# DSS_EDP0_V2A_CORE_VP_REGS_APB register map
Vendor: Texas Instruments
Peripheral module from a debugger description file (folder J7ES).
Registers are 32-bit, access per field, reset 0x0 unless marked. A register's access mark holds for its fields unless they carry their own. Offsets are as the file gives them; lines under a group give offsets from that group; [hi:lo] are bit positions; {n}, {i} and the like mark numbered series; 'fields as' and 'values as' point back to an identical list; <NAME> marks a mode.

## DSS_EDP0_V2A_CORE_VP_REGS_APB (part 1 of 3)
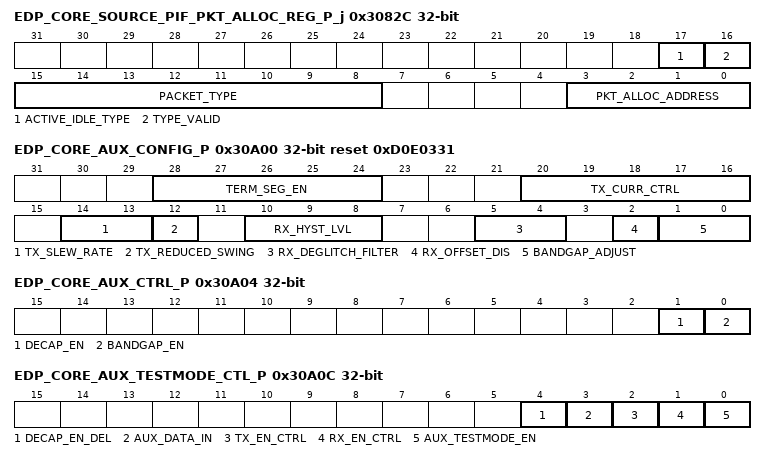
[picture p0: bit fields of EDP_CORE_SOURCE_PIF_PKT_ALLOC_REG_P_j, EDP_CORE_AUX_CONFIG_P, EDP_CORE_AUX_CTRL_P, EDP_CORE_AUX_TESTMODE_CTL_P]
0x3082C EDP_CORE_SOURCE_PIF_PKT_ALLOC_REG_P_j — Packet configuration to be stored in the allocation table Offset = 0003082Ch + (j * 40h); where j = 0h to 3h
  [17] ACTIVE_IDLE_TYPE rw — Indicates in which mode the SDP will be sent.
  [16] TYPE_VALID rw — 1 for valid, 0 for nonvalid
  [15:8] PACKET_TYPE rw
  [3:0] PKT_ALLOC_ADDRESS rw — Address of the register in the source allocation table
0x30830 EDP_CORE_SOURCE_PIF_PKT_ALLOC_WR_EN_P_j — Enable bit for writing to the allocation table Offset = 00030830h + (j * 40h); where j = 0h to 3h
  [0] PKT_ALLOC_WR_EN rw — Enable bit for writing to the allocation table, active high
0x30834 EDP_CORE_SOURCE_PIF_SW_RESET_P_j — Software reset. Offset = 00030834h + (j * 40h); where j = 0h to 3h
  [0] SW_RST rw — Software reset, active high.
0x30838 EDP_CORE_SOURCE_PIF_PPS_HEADER_P_j rw — PPS header Offset = 00030838h + (j * 40h); where j = 0h to 3h
  [31:0] PPS_HEADER — value of the PPS header as per DPv1.4
0x3083C EDP_CORE_SOURCE_PIF_PPS_P_j — PPS SDP indication Offset = 0003083Ch + (j * 40h); where j = 0h to 3h
  [0] PPS rw — PPS SDP indication, active high.
0x30A00 EDP_CORE_AUX_CONFIG_P reset 0xD0E0331 — AUX Configuration Register
  [28:24] TERM_SEG_EN rw — Enables output resistor segments for termination impedance.
  [20:16] TX_CURR_CTRL rw — TX current for output diff pair.
  [14:13] TX_SLEW_RATE rw — TX slew rate adjust.
  [12] TX_REDUCED_SWING rw — Control for lowering AUX transmitter swing level.
  [10:8] RX_HYST_LVL rw — Hysteresis control for AUX receiver front end.
  [5:4] RX_DEGLITCH_FILTER rw — Suppresses high-frequency pulses on AUX receiver output.
  [2] RX_OFFSET_DIS rw — Disables internal receiver cmn mode offset.
  [1:0] BANDGAP_ADJUST rw — Bandgap startup circuit adjust.
0x30A04 EDP_CORE_AUX_CTRL_P — AUX Control Register
  [1] DECAP_EN rw — Decap enable.
  [0] BANDGAP_EN rw — Bandgap enable.
0x30A08 EDP_CORE_AUX_ATBSEL_P — AUX_ATBSEL
  [7:0] AUXIP_ATBSEL_ONEHOT rw
0x30A0C EDP_CORE_AUX_TESTMODE_CTL_P — AUX IP test control register.
  [4] DECAP_EN_DEL rw — decap_en_del test value.
  [3] AUX_DATA_IN rw — aux_data_in test value.
  [2] TX_EN_CTRL rw — tx_en test value.
  [1] RX_EN_CTRL rw — rx_en test value.
  [0] AUX_TESTMODE_EN rw — AUX test enable.
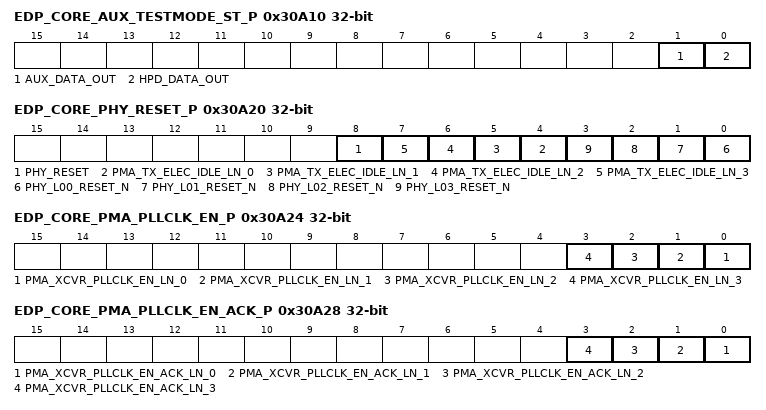
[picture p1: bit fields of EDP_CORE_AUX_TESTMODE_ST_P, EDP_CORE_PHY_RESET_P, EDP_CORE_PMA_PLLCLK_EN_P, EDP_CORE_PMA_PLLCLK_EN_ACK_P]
0x30A10 EDP_CORE_AUX_TESTMODE_ST_P ro — AUX IP interface status.
  [1] AUX_DATA_OUT — Raw status of aux_data_out output from AUX IP
  [0] HPD_DATA_OUT — Raw status of HPD output from AUX IP
0x30A20 EDP_CORE_PHY_RESET_P — PHY Reset Control Register
  [8] PHY_RESET rw
  [n+4] PMA_TX_ELEC_IDLE_LN_{n} rw (n=0..3) — PMA Tx electrical idle for line {n}.
  [n] PHY_L{n:02}_RESET_N rw (n=0..3)
0x30A24 EDP_CORE_PMA_PLLCLK_EN_P — PHY Link PLL Clock Enable Register
  [n] PMA_XCVR_PLLCLK_EN_LN_{n} rw (n=0..3) — Link PLL clock enable used to cleanly turn off the data rate clock in the PMA for line {n},
0x30A28 EDP_CORE_PMA_PLLCLK_EN_ACK_P ro — PHY Link PLL Clock Status Register
  [n] PMA_XCVR_PLLCLK_EN_ACK_LN_{n} (n=0..3) — Link PLL clock enable acknowledgement, indicates whether the data rate clock in the PMA for line {n} is running.
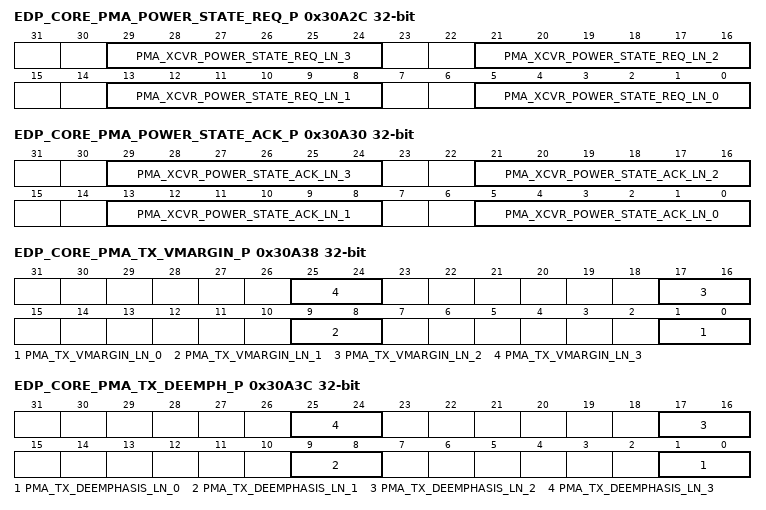
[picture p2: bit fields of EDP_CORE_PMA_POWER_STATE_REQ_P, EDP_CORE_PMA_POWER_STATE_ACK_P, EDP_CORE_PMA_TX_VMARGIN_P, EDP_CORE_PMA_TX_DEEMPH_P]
0x30A2C EDP_CORE_PMA_POWER_STATE_REQ_P — PHY Link Power State Request Register. Please refer to PHY Specification for detailed power state values
  [8n+5:8n] PMA_XCVR_POWER_STATE_REQ_LN_{n} rw (n=0..3) — Change the link power state.
0x30A30 EDP_CORE_PMA_POWER_STATE_ACK_P ro — PHY Link Power State Status Register
  [8n+5:8n] PMA_XCVR_POWER_STATE_ACK_LN_{n} (n=0..3) — Link power state acknowledgement, this signal provides indication that a power state change request has completed.
0x30A34 EDP_CORE_PMA_CMN_READY_P ro — PMA Operation Status Register
  [0] PMA_CMN_READY — PMA common ready,
0x30A38 EDP_CORE_PMA_TX_VMARGIN_P — PMA Tx Voltage Margin Control Register. Please refer to PHY Specification for Voltage Margin settings.
  [8n+1:8n] PMA_TX_VMARGIN_LN_{n} rw (n=0..3) — Drives PMA input tx_vmargin_ln_{n} for the associated lane.
0x30A3C EDP_CORE_PMA_TX_DEEMPH_P — PMA Tx Deemphasis Level Control Register. Please refer to PHY Specification for Deemphasis Level settings.
  [8n+1:8n] PMA_TX_DEEMPHASIS_LN_{n} rw (n=0..3) — Drives PMA input tx_deemphasis_ln_{n} for the associated lane.
0x30A60 EDP_CORE_ASF_IPS_CTRL reset 0x1 — ASF control register, imlemented only when ASF support is enabled in IP configuration
  [0] IF_ADDR_PARCHECK_EN rw — When set, enables parity check at APB/SAPB address bus.
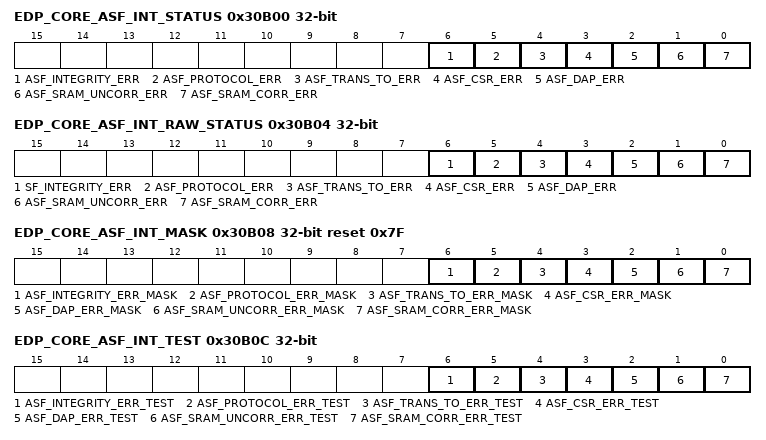
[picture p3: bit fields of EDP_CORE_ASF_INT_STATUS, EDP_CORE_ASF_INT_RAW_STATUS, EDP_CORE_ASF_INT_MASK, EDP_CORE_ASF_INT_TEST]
0x30B00 EDP_CORE_ASF_INT_STATUS — ASF Interrupt Status Register. This register indicates the source of ASF interrupts. The corresponding bit in the mask register must be clear for a bit to be set. If any bit is set in this register the asf_fatal or asf_nonfatal signal will be asserted. Writing to either raw or masked status registers, clear both registers. For test purposes, trigger signal interrupt event by writing to the ASF interrupt status test register.
  [6] ASF_INTEGRITY_ERR rw — Integrity error interrupt,1 is active, 0 is not active
  [5] ASF_PROTOCOL_ERR rw — Protocol error interrupt,1 is active, 0 is not active
  [4] ASF_TRANS_TO_ERR rw — Transaction timeouts error interrupt,1 is active, 0 is not active
  [3] ASF_CSR_ERR rw — Configuration and status registers error interrupt,1 is active, 0 is not active
  [2] ASF_DAP_ERR rw — Data and address paths parity error interrupt,1 is active, 0 is not active
  [1] ASF_SRAM_UNCORR_ERR rw — SRAM uncorrectable error interrupt,1 is active, 0 is not active
  [0] ASF_SRAM_CORR_ERR rw — SRAM correctable error interrupt,1 is active, 0 is not active
0x30B04 EDP_CORE_ASF_INT_RAW_STATUS — ASF Interrupt Raw Status Register. A bit set in this raw register indicates a source of ASF fault in the corresponding feature. Writing to either raw or masked status registers, clear both registers. For test purposes, trigger signal interrupt event by writing to the ASF interrupt status test register.
  [6] SF_INTEGRITY_ERR rw — Integrity error interrupt,1 is active, 0 is not active
  [5] ASF_PROTOCOL_ERR rw — Protocol error interrupt,1 is active, 0 is not active
  [4] ASF_TRANS_TO_ERR rw — Transaction timeouts error interrupt,1 is active, 0 is not active
  [3] ASF_CSR_ERR rw — Configuration and status registers error interrupt,1 is active, 0 is not active
  [2] ASF_DAP_ERR rw — Data and address paths parity error interrupt,1 is active, 0 is not active
  [1] ASF_SRAM_UNCORR_ERR rw — SRAM uncorrectable error interrupt,1 is active, 0 is not active
  [0] ASF_SRAM_CORR_ERR rw — SRAM correctable error interrupt,1 is active, 0 is not active
0x30B08 EDP_CORE_ASF_INT_MASK reset 0x7F — The ASF interrupt mask register indicating which interrupt bits in the ASF interrupt status register are masked. All bits are set at reset. Clear the individual bit to enable the corresponding interrupt.
  [6] ASF_INTEGRITY_ERR_MASK rw — Mask bit for Integrity error interrupt, 0 is active, 1 is not active.
  [5] ASF_PROTOCOL_ERR_MASK rw — Mask bit for Protocol error interrupt, 0 is active, 1 is not active.Interrupt from source which mask is 0 is permitted, otherwise interrupt is not permitted
  [4] ASF_TRANS_TO_ERR_MASK rw — Mask bit for Transaction timeouts error interrupt, 0 is active, 1 is not active.
  [3] ASF_CSR_ERR_MASK rw — Mask bit for Configuration and status registers error interrupt, 0 is active, 1 is not active.
  [2] ASF_DAP_ERR_MASK rw — Mask bit for Data and address paths parity error interrupt, 0 is active, 1 is not active.
  [1] ASF_SRAM_UNCORR_ERR_MASK rw — Mask bit for SRAM uncorrectable error interrupt, 0 is active, 1 is not active.
  [0] ASF_SRAM_CORR_ERR_MASK rw — Mask bit for SRAM correctable error interrupt, 0 is active, 1 is not active.
0x30B0C EDP_CORE_ASF_INT_TEST — The ASF interrupt test register emulate hardware even. Write one to individual bit to trigger single event in (masked and raw) status registers according to mask and will generate interrupt accordingly.
  [6] ASF_INTEGRITY_ERR_TEST rw — Test bit for Integrity error interrupt,1 is active, 0 is not active
  [5] ASF_PROTOCOL_ERR_TEST rw — Test bit for Protocol error interrupt,1 is active, 0 is not active
  [4] ASF_TRANS_TO_ERR_TEST rw — Test bit for Transaction timeouts error interrupt,1 is active, 0 is not active
  [3] ASF_CSR_ERR_TEST rw — Test bit for Configuration and status registers error interrupt,1 is active, 0 is not active
  [2] ASF_DAP_ERR_TEST rw — Test bit for Data and address paths parity error interrupt,1 is active, 0 is not active
  [1] ASF_SRAM_UNCORR_ERR_TEST rw — Test bit for SRAM uncorrectable error interrupt,1 is active, 0 is not active
  [0] ASF_SRAM_CORR_ERR_TEST rw — Test bit for SRAM correctable error interrupt,1 is active, 0 is not active
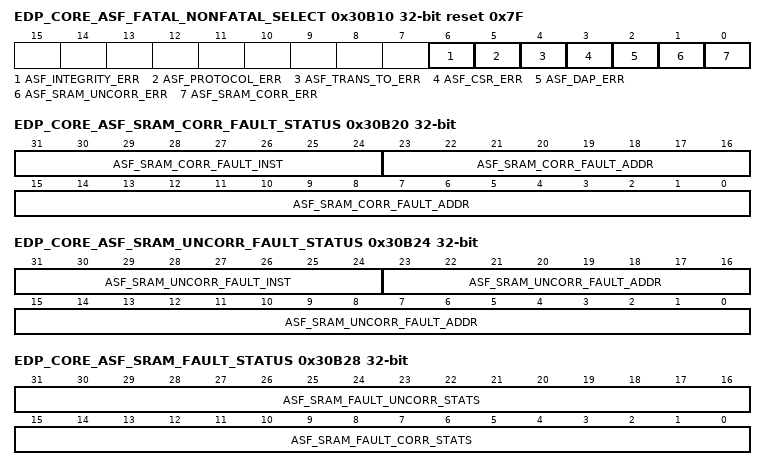
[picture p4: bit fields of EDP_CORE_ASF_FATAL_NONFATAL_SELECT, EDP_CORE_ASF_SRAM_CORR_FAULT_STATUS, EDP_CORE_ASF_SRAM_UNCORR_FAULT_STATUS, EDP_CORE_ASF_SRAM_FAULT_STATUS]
0x30B10 EDP_CORE_ASF_FATAL_NONFATAL_SELECT reset 0x7F — The fatal or non-fatal interrupt register selects whether a fatal (asf_int_fatal) or non-fatal (asf_int_nonfatal) interrupt is triggered. If the bit of the event will be set to one then fatal interrupt (asf_int_fatal) will be triggered. Otherwise the non-fatal interrupt (asf_int_nonfatal) will be triggered.
  [6] ASF_INTEGRITY_ERR rw — Enable Integrity error interrupt as fatal,1 is fatal interrupt, 0 is non-fatal
  [5] ASF_PROTOCOL_ERR rw — Enable Protocol error interrupt as fatal,1 is fatal interrupt, 0 is non-fatal
  [4] ASF_TRANS_TO_ERR rw — Enable Transaction timeouts error interrupt as fatal,1 is fatal interrupt, 0 is non-fatal
  [3] ASF_CSR_ERR rw — Enable Configuration and status registers error interrupt as fatal,1 is fatal interrupt, 0 is non-fatal
  [2] ASF_DAP_ERR rw — Enable Data and address paths parity error interrupt as fatal,1 is fatal interrupt, 0 is non-fatal
  [1] ASF_SRAM_UNCORR_ERR rw — Enable SRAM uncorrectable error interrupt as fatal,1 is fatal interrupt, 0 is non-fatal
  [0] ASF_SRAM_CORR_ERR rw — Enable SRAM correctable error interrupt as fatal,1 is fatal interrupt, 0 is non-fatal
0x30B20 EDP_CORE_ASF_SRAM_CORR_FAULT_STATUS ro — Status register for SRAM correctable fault. These fields are updated whenever asf_sram_corr_fault input is active.
  [31:24] ASF_SRAM_CORR_FAULT_INST — Last SRAM instance that generated fault
  [23:0] ASF_SRAM_CORR_FAULT_ADDR — Last SRAM address that generated fault
0x30B24 EDP_CORE_ASF_SRAM_UNCORR_FAULT_STATUS ro — Status register for SRAM uncorrectable fault. These fields are updated whenever asf_sram_uncorr_fault input is active.
  [31:24] ASF_SRAM_UNCORR_FAULT_INST — Last SRAM instance that generated fault
  [23:0] ASF_SRAM_UNCORR_FAULT_ADDR — Last SRAM address that generated fault
0x30B28 EDP_CORE_ASF_SRAM_FAULT_STATUS rw — Statistics register for SRAM faults. Note that this register clears when software writes to any field.
  [31:16] ASF_SRAM_FAULT_UNCORR_STATS — Count of number of uncorrectable errors if implemented.
  [15:0] ASF_SRAM_FAULT_CORR_STATS — Count of number of correctable errors if implemented.
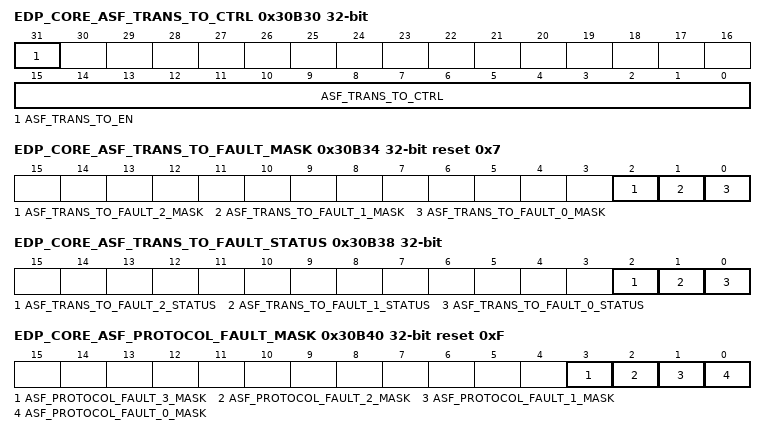
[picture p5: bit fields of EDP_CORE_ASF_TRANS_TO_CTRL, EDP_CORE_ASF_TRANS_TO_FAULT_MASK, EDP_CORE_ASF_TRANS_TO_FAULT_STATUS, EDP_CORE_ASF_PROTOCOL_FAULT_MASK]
0x30B30 EDP_CORE_ASF_TRANS_TO_CTRL — Control register to configure the ASF transaction timeout monitors.
  [31] ASF_TRANS_TO_EN rw — Enable transaction timeout monitoring,1 is active,0 is not active
  [15:0] ASF_TRANS_TO_CTRL rw — Timer value to use for transaction timeout monitor
0x30B34 EDP_CORE_ASF_TRANS_TO_FAULT_MASK reset 0x7 — Control register to mask out ASF transaction timeout faults from triggering interrupts. On reset, all bits are set to mask out all sources. Clear the corresponding bit to enable the interrupt source. The width of this field is parameterisable and the bit definitions are implementation specific.
  [2] ASF_TRANS_TO_FAULT_2_MASK rw — Mask bit for SAPB interface for transaction timeout fault,0 is active, 1 is not active.Interrupt from source which mask is 0 is permitted, otherwise interrupt is not permitted
  [1] ASF_TRANS_TO_FAULT_1_MASK rw — Mask bit for APB interface for transaction timeout fault,0 is active, 1 is not active.Interrupt from source which mask is 0 is permitted, otherwise interrupt is not permitted
  [0] ASF_TRANS_TO_FAULT_0_MASK rw — Mask bit for Xtensa watchdog error for transaction timeout fault,0 is active, 1 is not active.Interrupt from source which mask is 0 is permitted, otherwise interrupt is not permitted
0x30B38 EDP_CORE_ASF_TRANS_TO_FAULT_STATUS — Status register for transaction timeouts fault. If a fault occurs the revelant status bit will be set to 1. Each bit can be cleared by software writing 1 to each bit.
  [2] ASF_TRANS_TO_FAULT_2_STATUS rw — Status bits for SAPB interface for transaction timeout fault,1 is active, 0 is not active
  [1] ASF_TRANS_TO_FAULT_1_STATUS rw — Status bits for APB interface for transaction timeout fault,1 is active, 0 is not active
  [0] ASF_TRANS_TO_FAULT_0_STATUS rw — Status bits for Xtensa watchdog error for transaction timeout fault,1 is active, 0 is not active
0x30B40 EDP_CORE_ASF_PROTOCOL_FAULT_MASK reset 0xF — Control register to mask out ASF Protocol faults from triggering interrupts. On reset, all bits are set to mask out all sources. Clear the corresponding bit to enable the interrupt source. The width of this field is parameterisable and the bit definitions are implementation specific.
  [3] ASF_PROTOCOL_FAULT_3_MASK rw — Mask bit for FEC FSM fault.
  [2] ASF_PROTOCOL_FAULT_2_MASK rw — Mask bit for 8b10b Encoding fault from FEC module.
  [1] ASF_PROTOCOL_FAULT_1_MASK rw — Mask bit for Party Encoding fault from FEC module.
  [0] ASF_PROTOCOL_FAULT_0_MASK rw — Mask bit for Parity Generation fault from FEC module.
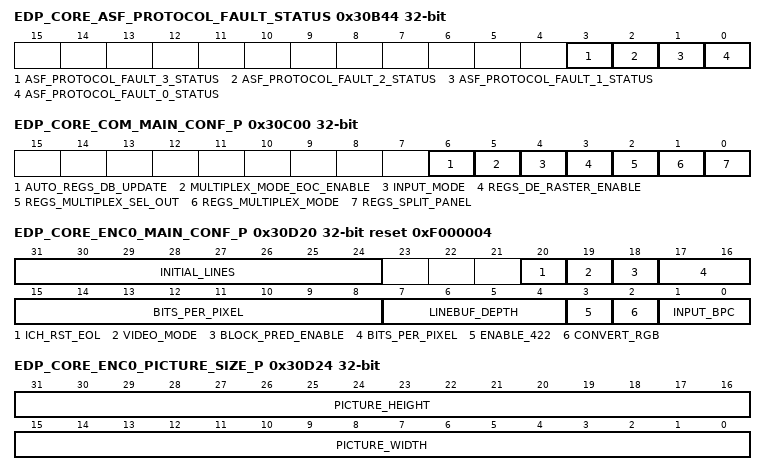
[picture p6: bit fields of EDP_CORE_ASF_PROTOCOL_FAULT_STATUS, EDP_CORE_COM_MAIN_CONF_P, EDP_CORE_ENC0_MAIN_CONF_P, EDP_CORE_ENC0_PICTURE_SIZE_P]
0x30B44 EDP_CORE_ASF_PROTOCOL_FAULT_STATUS — Status register for protocol faults. If a fault occurs the revelant status bit will be set to 1. Each bit can be cleared by software writing 1 to each bit
  [3] ASF_PROTOCOL_FAULT_3_STATUS rw — FEC symbol injection fault.
  [2] ASF_PROTOCOL_FAULT_2_STATUS rw — 8b10b Encoding fault in FEC module.
  [1] ASF_PROTOCOL_FAULT_1_STATUS rw — Party Encoding fault in FEC module.
  [0] ASF_PROTOCOL_FAULT_0_STATUS rw — Parity Generation fault in FEC module.
0x30C00 EDP_CORE_COM_MAIN_CONF_P — Encoder common configuration values
  [6] AUTO_REGS_DB_UPDATE rw — Active-High to enable auto update double buffer regs on vsync falling edge.
  [5] MULTIPLEX_MODE_EOC_ENABLE rw — When split_panel and multiplex_mode are set, indicates that multiplexer output separated chunks [inserts zeros on partial words at each end of chunk] and signal end of chunks.
  [4] INPUT_MODE rw — Video input interface mode:
  [3] REGS_DE_RASTER_ENABLE rw — Indicates if the De-Rasterization Buffer is used or bypassed: '1' Active '0' Bypassed
  [2] REGS_MULTIPLEX_SEL_OUT rw — When split_panel and multiplex_mode are set, indicates to which output the multiplexed stream is sent: '0': enc0_data_out '1': enc1_data_out
  [1] REGS_MULTIPLEX_MODE rw — Active-High, indicates that both encoders are used to produce a multiplex stream on a single Transport link.
  [0] REGS_SPLIT_PANEL rw — Active-High, indicates that both encoders are used in parallel for one video stream [L and R split].
0x30D20 EDP_CORE_ENC0_MAIN_CONF_P reset 0xF000004 — Encoder Main Configuration values
  [31:24] INITIAL_LINES rw — Number of lines to wait before initiating transport in Command Mode.
  [20] ICH_RST_EOL rw — Forces the ICH to reset at EOL [when not in split mode].
  [19] VIDEO_MODE rw — MIPI Video/Command mode: '0' Command mode '1' Video mode
  [18] BLOCK_PRED_ENABLE rw — Active-High input Block Prediction Enable
  [17:8] BITS_PER_PIXEL rw — Target bits per pixel.
  [7:4] LINEBUF_DEPTH rw — Depth of the line buffer used by the decoder [i.e., the number of bits stored for each component of the pixels on the previous line]
  [3] ENABLE_422 rw — Active-High input to indicate the data_in pixels are
  [2] CONVERT_RGB rw — Active-High input to indicate the data_in pixels are RGB.
  [1:0] INPUT_BPC rw — Indicates the current input pixel stream bits per component:
0x30D24 EDP_CORE_ENC0_PICTURE_SIZE_P rw — Encoder Picture configuration
  [31:16] PICTURE_HEIGHT, [15:0] PICTURE_WIDTH
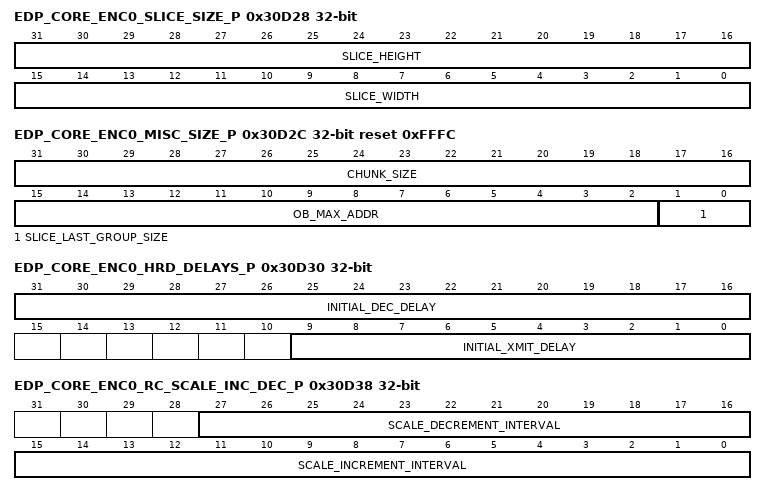
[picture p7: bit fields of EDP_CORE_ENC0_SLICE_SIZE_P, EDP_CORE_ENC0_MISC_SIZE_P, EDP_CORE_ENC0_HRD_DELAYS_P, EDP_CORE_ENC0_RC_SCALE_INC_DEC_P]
0x30D28 EDP_CORE_ENC0_SLICE_SIZE_P rw — Encoder Slice(s) configuration
  [31:16] SLICE_HEIGHT, [15:0] SLICE_WIDTH
0x30D2C EDP_CORE_ENC0_MISC_SIZE_P rw reset 0xFFFC — Encoder Group, Output Buffer(s), and Transport Chunk Size
  [31:16] CHUNK_SIZE — Chunk size in bytes
  [15:2] OB_MAX_ADDR — Output Buffer[s] max pointer address[es]
  [1:0] SLICE_LAST_GROUP_SIZE — Size of last group of the slice line
0x30D30 EDP_CORE_ENC0_HRD_DELAYS_P — Hypothetical Reference Decoder delays
  [31:16] INITIAL_DEC_DELAY rw — Initial Decoder delay
  [9:0] INITIAL_XMIT_DELAY rw — Initial Decoder Transmit delay
0x30D34 EDP_CORE_ENC0_RC_SCALE_P — RC Calculate Buffer Fullness and Offset, Scale value
  [5:0] INITIAL_SCALE_VALUE rw — Three fractional bits
0x30D38 EDP_CORE_ENC0_RC_SCALE_INC_DEC_P — RC Calculate Buffer Fullness and Offset, Increment and Decrement Scale values
  [27:16] SCALE_DECREMENT_INTERVAL rw — RC scale decrement value
  [15:0] SCALE_INCREMENT_INTERVAL rw — RC scale increment value
0x30D3C EDP_CORE_ENC0_RC_OFFSETS_1_P — RC Calculate Buffer Fullness and Offset, Various Offset control values 1
  [4:0] FIRST_LINE_BPG_OFFSET rw — First Line
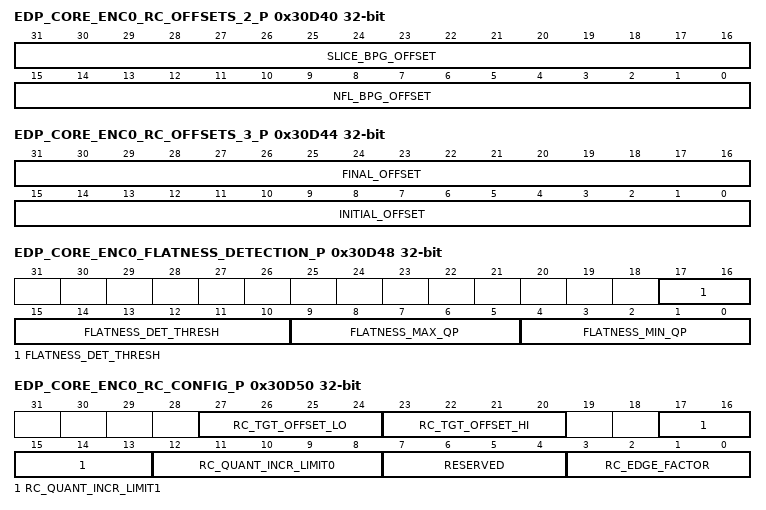
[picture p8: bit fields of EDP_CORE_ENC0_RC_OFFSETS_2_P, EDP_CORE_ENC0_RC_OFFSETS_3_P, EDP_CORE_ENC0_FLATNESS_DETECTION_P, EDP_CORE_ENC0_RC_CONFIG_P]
0x30D40 EDP_CORE_ENC0_RC_OFFSETS_2_P rw — RC Calculate Buffer Fullness and Offset, Various Offset control values 2
  [31:16] SLICE_BPG_OFFSET — Extra budget per group [11 fractional bits]
  [15:0] NFL_BPG_OFFSET — Non First Line [11 fractional bits]
0x30D44 EDP_CORE_ENC0_RC_OFFSETS_3_P rw — RC Calculate Buffer Fullness and Offset, Various Offset control values 3
  [31:16] FINAL_OFFSET, [15:0] INITIAL_OFFSET
0x30D48 EDP_CORE_ENC0_FLATNESS_DETECTION_P — Flatness Signaling QP Override thresholds
  [17:10] FLATNESS_DET_THRESH rw — Flatness Detection Threshold, as defined in PPS table of the DSC specification
  [9:5] FLATNESS_MAX_QP rw — Maximum threshold
  [4:0] FLATNESS_MIN_QP rw — Minimum threshold
0x30D4C EDP_CORE_ENC0_RC_MODEL_SIZE_P — RC Model Size
  [15:0] RC_MODEL_SIZE rw
0x30D50 EDP_CORE_ENC0_RC_CONFIG_P — RC Model Various Config
  [27:24] RC_TGT_OFFSET_LO rw — RC Target offset low
  [23:20] RC_TGT_OFFSET_HI rw — RC Target offset high
  [17:13] RC_QUANT_INCR_LIMIT1 rw — RC quantization increment limit 1
  [12:8] RC_QUANT_INCR_LIMIT0 rw — RC quantization increment limit 0
  [7:4] RESERVED ro — RC Edge factor [1 fractional bit]
  [3:0] RC_EDGE_FACTOR rw — Reserved.
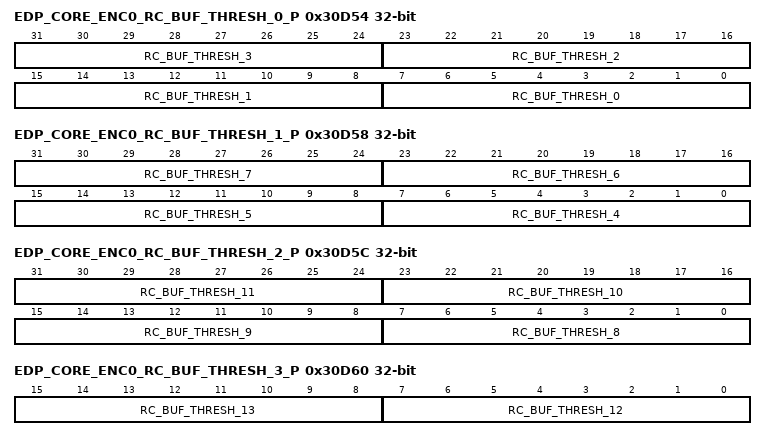
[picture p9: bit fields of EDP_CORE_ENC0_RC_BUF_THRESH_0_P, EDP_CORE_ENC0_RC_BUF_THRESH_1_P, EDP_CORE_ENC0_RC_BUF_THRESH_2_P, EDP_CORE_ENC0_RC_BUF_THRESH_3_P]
0x30D54 EDP_CORE_ENC0_RC_BUF_THRESH_0_P rw — RC Model Buffer Thresholds 0
  [8n+7:8n] RC_BUF_THRESH_{n} (n=0..3) — 8 MSBs of the value.
0x30D58 EDP_CORE_ENC0_RC_BUF_THRESH_1_P rw — RC Model Buffer Thresholds 1
  [8n-25:8n-32] RC_BUF_THRESH_{n} (n=4..7) — 8 MSBs of the value.
0x30D5C EDP_CORE_ENC0_RC_BUF_THRESH_2_P rw — RC Model Buffer Thresholds 2
  [8n-57:8n-64] RC_BUF_THRESH_{n} (n=8..11) — 8 MSBs of the value.
0x30D60 EDP_CORE_ENC0_RC_BUF_THRESH_3_P — RC Model Buffer Thresholds 3
  [15:8] RC_BUF_THRESH_13 rw — 8 MSBs of the value.
  [7:0] RC_BUF_THRESH_12 rw — 8 MSBs of the value.
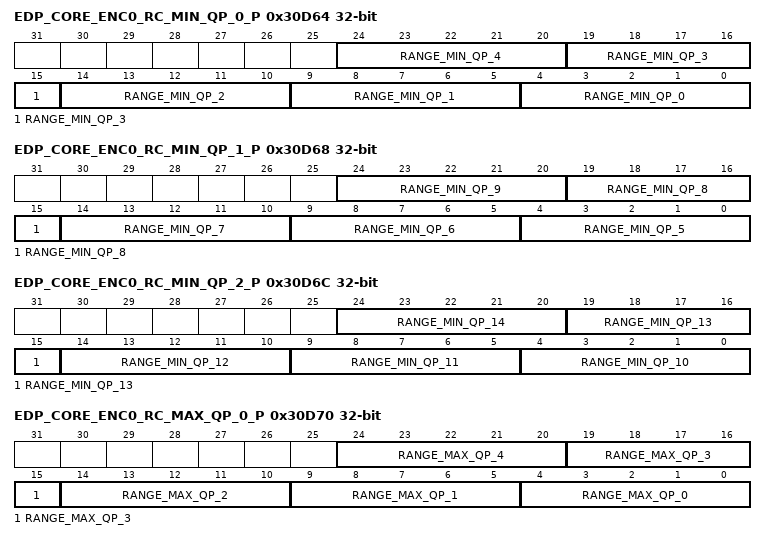
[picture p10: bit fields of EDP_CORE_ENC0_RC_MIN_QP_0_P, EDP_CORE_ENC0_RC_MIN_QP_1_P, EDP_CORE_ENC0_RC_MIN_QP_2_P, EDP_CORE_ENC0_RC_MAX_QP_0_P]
0x30D64 EDP_CORE_ENC0_RC_MIN_QP_0_P — RC Min QP 0
  [5n+4:5n] RANGE_MIN_QP_{n} rw (n=0..4) — As per DSC specification
0x30D68 EDP_CORE_ENC0_RC_MIN_QP_1_P — RC Min QP 1
  [5n-21:5n-25] RANGE_MIN_QP_{n} rw (n=5..9) — As per DSC specification
0x30D6C EDP_CORE_ENC0_RC_MIN_QP_2_P — RC Min QP 2
  [5n-46:5n-50] RANGE_MIN_QP_{n} rw (n=10..14) — As per DSC specification
0x30D70 EDP_CORE_ENC0_RC_MAX_QP_0_P — RC Max QP 0
  [5n+4:5n] RANGE_MAX_QP_{n} rw (n=0..4) — As per DSC specification
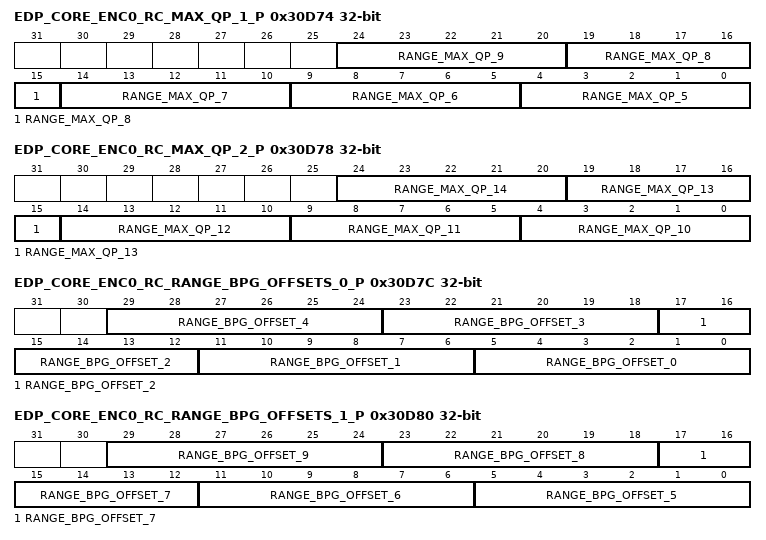
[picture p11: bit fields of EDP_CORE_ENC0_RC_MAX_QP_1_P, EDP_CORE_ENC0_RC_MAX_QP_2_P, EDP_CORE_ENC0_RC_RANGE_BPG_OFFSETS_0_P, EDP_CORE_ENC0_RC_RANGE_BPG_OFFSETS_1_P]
0x30D74 EDP_CORE_ENC0_RC_MAX_QP_1_P — RC Max QP 1
  [5n-21:5n-25] RANGE_MAX_QP_{n} rw (n=5..9) — As per DSC specification
0x30D78 EDP_CORE_ENC0_RC_MAX_QP_2_P — RC Max QP 2
  [5n-46:5n-50] RANGE_MAX_QP_{n} rw (n=10..14) — As per DSC specification
0x30D7C EDP_CORE_ENC0_RC_RANGE_BPG_OFFSETS_0_P — RC Range bpg Offsets 0
  [6n+5:6n] RANGE_BPG_OFFSET_{n} rw (n=0..4) — As per DSC specification
0x30D80 EDP_CORE_ENC0_RC_RANGE_BPG_OFFSETS_1_P — RC Range bpg Offsets 1
  [6n-25:6n-30] RANGE_BPG_OFFSET_{n} rw (n=5..9) — As per DSC specification
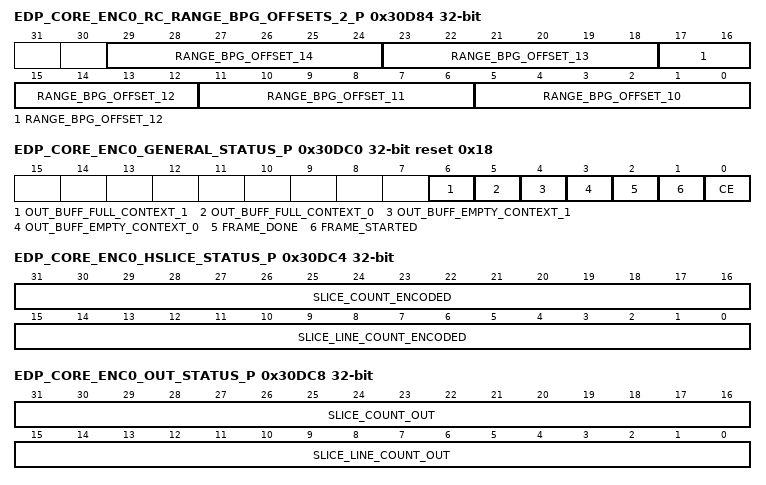
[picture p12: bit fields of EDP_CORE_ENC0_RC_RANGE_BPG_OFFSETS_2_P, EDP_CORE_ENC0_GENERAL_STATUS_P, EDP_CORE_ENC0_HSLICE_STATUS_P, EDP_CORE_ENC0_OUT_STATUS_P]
0x30D84 EDP_CORE_ENC0_RC_RANGE_BPG_OFFSETS_2_P — RC Range bpg Offsets 2
  [6n-55:6n-60] RANGE_BPG_OFFSET_{n} rw (n=10..14) — As per DSC specification
0x30D88 EDP_CORE_ENC0_DPI_CTRL_OUT_DELAY_P — Delay applied to DPI input control signals to generate DPI output control signals
  [15:0] DPI_CTRL_OUT_DELAY rw — Delay in number of encx clock cycles.
0x30DC0 EDP_CORE_ENC0_GENERAL_STATUS_P ro reset 0x18 — General Encoder Status
  [6] OUT_BUFF_FULL_CONTEXT_1 — Output buffer 1 [soft slice 1] is full.For Debug purposes only.
  [5] OUT_BUFF_FULL_CONTEXT_0 — Output buffer 0 [soft slice 0] is full.For Debug purposes only.
  [4] OUT_BUFF_EMPTY_CONTEXT_1 — Output buffer 1 [soft slice 1] is empty.For Debug purposes only.
  [3] OUT_BUFF_EMPTY_CONTEXT_0 — Output buffer 0 [soft slice 0] is empty.For Debug purposes only.
  [2] FRAME_DONE — Encoder finished a frame
  [1] FRAME_STARTED — Encoder is currently processing a frame
  [0] CE — Flow control internal clock enable status.For Debug purposes only.
0x30DC4 EDP_CORE_ENC0_HSLICE_STATUS_P ro — Hard Slice Encoded Status
  [31:16] SLICE_COUNT_ENCODED — Actual slice number of current frame being processed at VLC encoder.Not re-synchronized in register clock domain.
  [15:0] SLICE_LINE_COUNT_ENCODED — Actual line number of current slice being processed at VLC encoder.Not re-synchronized in register clock domain.
0x30DC8 EDP_CORE_ENC0_OUT_STATUS_P ro — Outputted Slice Status
  [31:16] SLICE_COUNT_OUT — Actual slice number of current frame being read at output interface.Not re-synchronized in register clock domain.
  [15:0] SLICE_LINE_COUNT_OUT — Actual line number of current slice being read at output interface.Not re-synchronized in register clock domain.
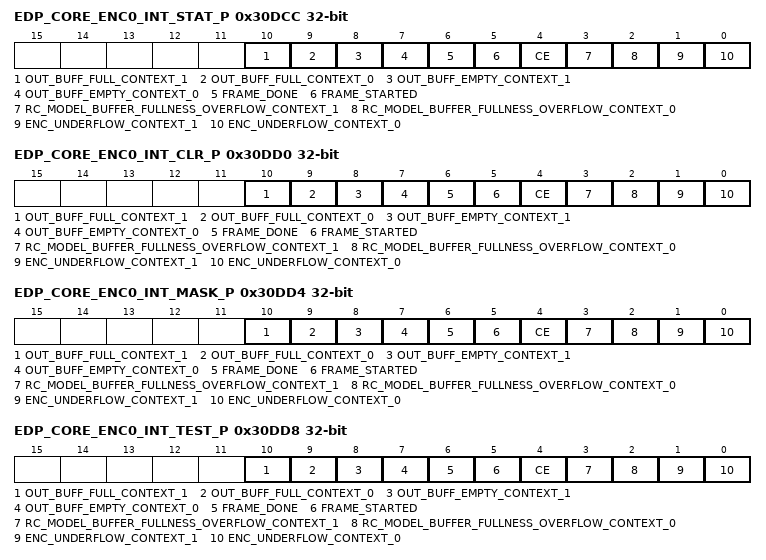
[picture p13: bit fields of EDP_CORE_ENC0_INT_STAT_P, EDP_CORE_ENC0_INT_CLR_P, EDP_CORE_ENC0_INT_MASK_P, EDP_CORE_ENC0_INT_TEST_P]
0x30DCC EDP_CORE_ENC0_INT_STAT_P ro — Encoder Interrupt Status
  [10] OUT_BUFF_FULL_CONTEXT_1 — Output buffer 1 [soft slice 1] became full
  [9] OUT_BUFF_FULL_CONTEXT_0 — Output buffer 0 [soft slice 0] became full
  [8] OUT_BUFF_EMPTY_CONTEXT_1 — Output buffer 1 [soft slice 1] became empty
  [7] OUT_BUFF_EMPTY_CONTEXT_0 — Output buffer 0 [soft slice 0] became empty
  [6] FRAME_DONE — Encoder finished a frame
  [5] FRAME_STARTED — Encoder is started to process a frame
  [4] CE — Flow control internal clock enable becomes high
  [3] RC_MODEL_BUFFER_FULLNESS_OVERFLOW_CONTEXT_1 — rc_model_buffer 1 [soft slice 1] overflow
  [2] RC_MODEL_BUFFER_FULLNESS_OVERFLOW_CONTEXT_0 — rc_model_buffer 0 [soft slice 0] overflow
  [1] ENC_UNDERFLOW_CONTEXT_1 — output buffer 1 [soft slice 1] underflow
  [0] ENC_UNDERFLOW_CONTEXT_0 — output buffer 0 [soft slice 0] underflow
0x30DD0 EDP_CORE_ENC0_INT_CLR_P — Encoder Interrupt Clear. Setting any one of these bits, clears the corresponding ENC_INT_STAT bits. This register is self-clearing after 8 regs_pclk cycles.
  [10] OUT_BUFF_FULL_CONTEXT_1 rw — Output buffer 1 [soft slice 1] became full
  [9] OUT_BUFF_FULL_CONTEXT_0 rw — Output buffer 0 [soft slice 0] became full
  [8] OUT_BUFF_EMPTY_CONTEXT_1 rw — Output buffer 1 [soft slice 1] became empty
  [7] OUT_BUFF_EMPTY_CONTEXT_0 rw — Output buffer 0 [soft slice 0] became empty
  [6] FRAME_DONE rw — Encoder finished a frame
  [5] FRAME_STARTED rw — Encoder is started to process a frame
  [4] CE rw — Flow control internal clock enable
  [3] RC_MODEL_BUFFER_FULLNESS_OVERFLOW_CONTEXT_1 rw — rc model buffer 1 overflow
  [2] RC_MODEL_BUFFER_FULLNESS_OVERFLOW_CONTEXT_0 rw — rc model buffer 0 overflow
  [1] ENC_UNDERFLOW_CONTEXT_1 rw — output buffer 1 underflow
  [0] ENC_UNDERFLOW_CONTEXT_0 rw — output buffer 0 underflow
0x30DD4 EDP_CORE_ENC0_INT_MASK_P — Encoder Interrupt Mask. Any bit set to 1'b1 is enabled to report an interrupt on the corresponding bit position
  [10] OUT_BUFF_FULL_CONTEXT_1 rw — Output buffer 1 [soft slice 1] became full
  [9] OUT_BUFF_FULL_CONTEXT_0 rw — Output buffer 0 [soft slice 0] became full
  [8] OUT_BUFF_EMPTY_CONTEXT_1 rw — Output buffer 1 [soft slice 1] became empty
  [7] OUT_BUFF_EMPTY_CONTEXT_0 rw — Output buffer 0 [soft slice 0] became empty
  [6] FRAME_DONE rw — Encoder finished a frame
  [5] FRAME_STARTED rw — Encoder is started to process a frame
  [4] CE rw — Flow control internal clock enable
  [3] RC_MODEL_BUFFER_FULLNESS_OVERFLOW_CONTEXT_1 rw — rc model buffer 1 overflow
  [2] RC_MODEL_BUFFER_FULLNESS_OVERFLOW_CONTEXT_0 rw — rc model buffer 0 overflow
  [1] ENC_UNDERFLOW_CONTEXT_1 rw — enc underflow 1 underflow
  [0] ENC_UNDERFLOW_CONTEXT_0 rw — enc underflow 0 underflow
0x30DD8 EDP_CORE_ENC0_INT_TEST_P — Encoder Interrupt Test. Setting any one of these bits to 0x0 and then to 0x1 simulate a hardware event and generate an interrupt if the corresponding ENCx_INT_MASK bit is set.
  [10] OUT_BUFF_FULL_CONTEXT_1 rw — Output buffer 1 [soft slice 1] became full test
  [9] OUT_BUFF_FULL_CONTEXT_0 rw — Output buffer 0 [soft slice 0] became full test
  [8] OUT_BUFF_EMPTY_CONTEXT_1 rw — Output buffer 1 [soft slice 1] became empty test
  [7] OUT_BUFF_EMPTY_CONTEXT_0 rw — Output buffer 0 [soft slice 0] became empty test
  [6] FRAME_DONE rw — Encoder finished a frame test
  [5] FRAME_STARTED rw — Encoder is started to process a frame test
  [4] CE rw — Flow control internal clock enable test
  [3] RC_MODEL_BUFFER_FULLNESS_OVERFLOW_CONTEXT_1 rw — rc model buffer 1 overflow test
  [2] RC_MODEL_BUFFER_FULLNESS_OVERFLOW_CONTEXT_0 rw — rc model buffer 0 overflow test
  [1] ENC_UNDERFLOW_CONTEXT_1 rw — enc underflow 1 underflow test
  [0] ENC_UNDERFLOW_CONTEXT_0 rw — enc underflow 0 underflow test
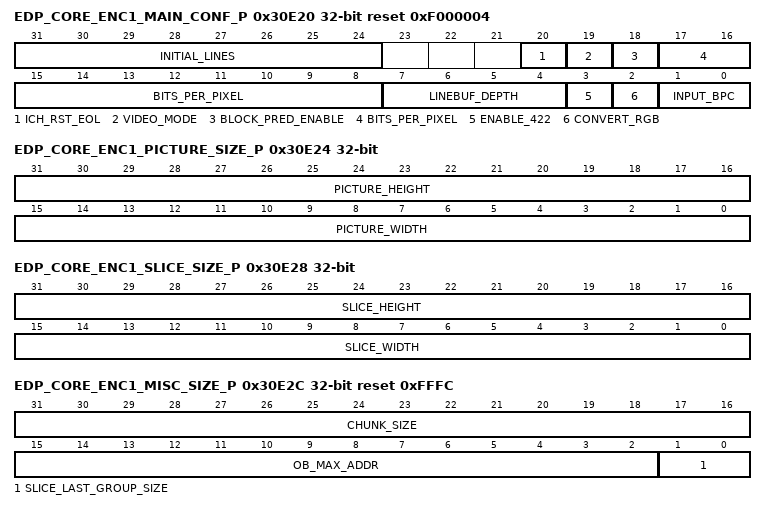
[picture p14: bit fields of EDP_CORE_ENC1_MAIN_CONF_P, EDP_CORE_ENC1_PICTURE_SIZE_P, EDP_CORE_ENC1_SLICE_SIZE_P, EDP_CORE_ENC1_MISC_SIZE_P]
0x30E20 EDP_CORE_ENC1_MAIN_CONF_P reset 0xF000004 — Encoder Main Configuration values test
  fields as EDP_CORE_ENC0_MAIN_CONF_P
0x30E24 EDP_CORE_ENC1_PICTURE_SIZE_P rw — Encoder Picture configuration
  [31:16] PICTURE_HEIGHT, [15:0] PICTURE_WIDTH
0x30E28 EDP_CORE_ENC1_SLICE_SIZE_P rw — Encoder Slice(s) configuration
  [31:16] SLICE_HEIGHT, [15:0] SLICE_WIDTH
0x30E2C EDP_CORE_ENC1_MISC_SIZE_P rw reset 0xFFFC — Encoder Group, Output Buffer(s), and Transport Chunk Size
  fields as EDP_CORE_ENC0_MISC_SIZE_P
0x30E30 EDP_CORE_ENC1_HRD_DELAYS_P — Hypothetical Reference Decoder delays
  fields as EDP_CORE_ENC0_HRD_DELAYS_P
0x30E34 EDP_CORE_ENC1_RC_SCALE_P — RC Calculate Buffer Fullness and Offset, Scale value
  [5:0] INITIAL_SCALE_VALUE rw — Three fractional bits
0x30E38 EDP_CORE_ENC1_RC_SCALE_INC_DEC_P — RC Calculate Buffer Fullness and Offset, Increment and Decrement Scale values
  fields as EDP_CORE_ENC0_RC_SCALE_INC_DEC_P
0x30E3C EDP_CORE_ENC1_RC_OFFSETS_1_P — RC Calculate Buffer Fullness and Offset, Various Offset control values 1
  [4:0] FIRST_LINE_BPG_OFFSET rw — First Line
0x30E40 EDP_CORE_ENC1_RC_OFFSETS_2_P rw — RC Calculate Buffer Fullness and Offset, Various Offset control values 2
  fields as EDP_CORE_ENC0_RC_OFFSETS_2_P
0x30E44 EDP_CORE_ENC1_RC_OFFSETS_3_P rw — RC Calculate Buffer Fullness and Offset, Various Offset control values 3
  [31:16] FINAL_OFFSET, [15:0] INITIAL_OFFSET
0x30E48 EDP_CORE_ENC1_FLATNESS_DETECTION_P — Flatness Signaling QP Override thresholds
  fields as EDP_CORE_ENC0_FLATNESS_DETECTION_P
0x30E4C EDP_CORE_ENC1_RC_MODEL_SIZE_P — RC Model Size
  [15:0] RC_MODEL_SIZE rw
0x30E50 EDP_CORE_ENC1_RC_CONFIG_P — RC Model Various Config
  fields as EDP_CORE_ENC0_RC_CONFIG_P
0x30E54 EDP_CORE_ENC1_RC_BUF_THRESH_0_P rw — RC Model Buffer Thresholds 0
  [8n+7:8n] RC_BUF_THRESH_{n} (n=0..3) — 8 MSBs of the value.
0x30E58 EDP_CORE_ENC1_RC_BUF_THRESH_1_P rw — RC Model Buffer Thresholds 1
  [8n-25:8n-32] RC_BUF_THRESH_{n} (n=4..7) — 8 MSBs of the value.
0x30E5C EDP_CORE_ENC1_RC_BUF_THRESH_2_P rw — RC Model Buffer Thresholds 2
  [8n-57:8n-64] RC_BUF_THRESH_{n} (n=8..11) — 8 MSBs of the value.
0x30E60 EDP_CORE_ENC1_RC_BUF_THRESH_3_P — RC Model Buffer Thresholds 3
  [31:16] RESERVED ro — 8 MSBs of the value.
  [15:8] RC_BUF_THRESH_13 rw — 8 MSBs of the value.
  [7:0] RC_BUF_THRESH_12 rw — 8 MSBs of the value.
0x30E64 EDP_CORE_ENC1_RC_MIN_QP_0_P — RC Min QP 0
  [5n+4:5n] RANGE_MIN_QP_{n} rw (n=0..4) — As per DSC specification
0x30E68 EDP_CORE_ENC1_RC_MIN_QP_1_P — RC Min QP 1
  fields as EDP_CORE_ENC0_RC_MIN_QP_1_P
0x30E6C EDP_CORE_ENC1_RC_MIN_QP_2_P — RC Min QP 2
  fields as EDP_CORE_ENC0_RC_MIN_QP_2_P
0x30E70 EDP_CORE_ENC1_RC_MAX_QP_0_P — RC Max QP 0
  [5n+4:5n] RANGE_MAX_QP_{n} rw (n=0..4) — As per DSC specification
0x30E74 EDP_CORE_ENC1_RC_MAX_QP_1_P — RC Max QP 1
  fields as EDP_CORE_ENC0_RC_MAX_QP_1_P
0x30E78 EDP_CORE_ENC1_RC_MAX_QP_2_P — RC Max QP 2
  fields as EDP_CORE_ENC0_RC_MAX_QP_2_P
0x30E7C EDP_CORE_ENC1_RC_RANGE_BPG_OFFSETS_0_P — RC Range bpg Offsets 0
  fields as EDP_CORE_ENC0_RC_RANGE_BPG_OFFSETS_0_P
0x30E80 EDP_CORE_ENC1_RC_RANGE_BPG_OFFSETS_1_P — RC Range bpg Offsets 1
  fields as EDP_CORE_ENC0_RC_RANGE_BPG_OFFSETS_1_P
0x30E84 EDP_CORE_ENC1_RC_RANGE_BPG_OFFSETS_2_P — RC Range bpg Offsets 2
  fields as EDP_CORE_ENC0_RC_RANGE_BPG_OFFSETS_2_P
0x30E88 EDP_CORE_ENC1_DPI_CTRL_OUT_DELAY_P — Delay applied to DPI input control signals to generate DPI output control signals
  [15:0] DPI_CTRL_OUT_DELAY rw — Delay in number of encx clock cycles.
0x30EC0 EDP_CORE_ENC1_GENERAL_STATUS_P ro reset 0x18 — General Encoder Status
  fields as EDP_CORE_ENC0_GENERAL_STATUS_P
0x30EC4 EDP_CORE_ENC1_HSLICE_STATUS_P ro — Hard Slice Encoded Status
  fields as EDP_CORE_ENC0_HSLICE_STATUS_P
0x30EC8 EDP_CORE_ENC1_OUT_STATUS_P ro — Outputted Slice Status
  fields as EDP_CORE_ENC0_OUT_STATUS_P
0x30ECC EDP_CORE_ENC1_INT_STAT_P ro — Encoder Interrupt Status
  [10] OUT_BUFF_FULL_CONTEXT_1 — Output buffer 1 [soft slice 1] became full
  [9] OUT_BUFF_FULL_CONTEXT_0 — Output buffer 0 [soft slice 0] became full
  [8] OUT_BUFF_EMPTY_CONTEXT_1 — Output buffer 1 [soft slice 1] became empty
  [7] OUT_BUFF_EMPTY_CONTEXT_0 — Output buffer 0 [soft slice 0] became empty
  [6] FRAME_DONE — Encoder finished a frame
  [5] FRAME_STARTED — Encoder is started to process a frame
  [4] CE — Flow control internal clock enable becomes high
  [3] RC_MODEL_BUFFER_FULLNESS_OVERFLOW_CONTEXT_1 — output buffer 1 [soft slice 1] underflow
  [2] RC_MODEL_BUFFER_FULLNESS_OVERFLOW_CONTEXT_0 — output buffer 0 [soft slice 0] underflow
  [1] ENC_UNDERFLOW_CONTEXT_1 — output buffer 1 [soft slice 1] underflow
  [0] ENC_UNDERFLOW_CONTEXT_0 — output buffer 0 [soft slice 0] underflow
0x30ED0 EDP_CORE_ENC1_INT_CLR_P — Encoder Interrupt Clear. Setting any one of these bits, clears the corresponding ENC_INT_STAT bits. This register is self-clearing after 8 regs_pclk cycles.
  fields as EDP_CORE_ENC0_INT_CLR_P
0x30ED4 EDP_CORE_ENC1_INT_MASK_P — Encoder Interrupt Mask. Any bit set to 1'b1 is enabled to report an interrupt on the corresponding bit position
  fields as EDP_CORE_ENC0_INT_MASK_P
0x30ED8 EDP_CORE_ENC1_INT_TEST_P — Encoder Interrupt Test. Setting any one of these bits to 0x0 and then to 0x1 simulate a hardware event and generate an interrupt if the corresponding ENCx_INT_MASK bit is set.
  fields as EDP_CORE_ENC0_INT_TEST_P
0x30F00 EDP_CORE_ENC_ASF_INT_STAT_P — Encoder ASF Interrupt Status
  [8] ASF_CSR_ERR ro — Configuration and status registers uncorrectable error interrupt
  [7] ENC1_SELF_CHK_ERR ro — Hard Slice 1 Encoder self-check uncorrectable error interrupt
  [6] ENC1_OUT_CHK_ERR ro — Hard Slice 1 Encoder output checker uncorrectable error interrupt
  [5] ENC1_ASF_SRAM_UNCORR_ERR ro — Hard Slice 1 SRAM uncorrectable error interrupt
  [4] ENC1_ASF_SRAM_CORR_ERR ro — Hard Slice 1 SRAM correctable error interrupt
  [3] ENC0_SELF_CHK_ERR ro — Hard Slice 0 Encoder self-check uncorrectable error interrupt
  [2] ENC0_OUT_CHK_ERR ro — Hard Slice 0 Encoder output checker uncorrectable error interrupt
  [1] ENC0_ASF_SRAM_UNCORR_ERR rw — Hard Slice 0 SRAM uncorrectable error interrupt
  [0] ENC0_ASF_SRAM_CORR_ERR ro — Hard Slice 0 SRAM correctable error interrupt
0x30F04 EDP_CORE_ENC_ASF_INT_MASK_P — Encoder ASF Interrupt Mask. Any bit set to 1'b1 is enabled to report an interrupt on the corresponding bit position
  [8] ASF_CSR_ERR rw — Configuration and status registers uncorrectable error interrupt
  [7] ENC1_SELF_CHK_ERR rw — Hard Slice 1 Encoder self-check uncorrectable error interrupt
  [6] ENC1_OUT_CHK_ERR rw — Hard Slice 1 Encoder output checker uncorrectable error interrupt
  [5] ENC1_ASF_SRAM_UNCORR_ERR rw — Hard Slice 1 SRAM uncorrectable error interrupt
  [4] ENC1_ASF_SRAM_CORR_ERR rw — Hard Slice 1 SRAM correctable error interrupt
  [3] ENC0_SELF_CHK_ERR rw — Hard Slice 0 Encoder self-check uncorrectable error interrupt
  [2] ENC0_OUT_CHK_ERR rw — Hard Slice 0 Encoder output checker uncorrectable error interrupt
  [1] ENC0_ASF_SRAM_UNCORR_ERR rw — Hard Slice 0 SRAM uncorrectable error interrupt
  [0] ENC0_ASF_SRAM_CORR_ERR rw — Hard Slice 0 SRAM correctable error interrupt
0x30F08 EDP_CORE_ENC_ASF_INT_CLR_P — Encoder ASF Interrupt Clear. Setting any one of these bits, clears the corresponding ENC_ASF_INT_STAT bits
  fields as EDP_CORE_ENC_ASF_INT_MASK_P
0x30F0C EDP_CORE_ENC_ASF_INT_TEST_P — Encoder ASF Interrupt Test. Setting any one of these bits to 0x0 and then to 0x1 simulate a hardware event and generate an interrupt if the corresponding ENC_ASF_INT_MASK bit is set
  [8] ASF_CSR_ERR rw — Configuration and status registers uncorrectable error interrupt test
  [7] ENC1_SELF_CHK_ERR rw — Hard Slice 1 Encoder self-check uncorrectable error interrupt test
  [6] ENC1_OUT_CHK_ERR rw — Hard Slice 1 Encoder output checker uncorrectable error interrupt test
  [5] ENC1_ASF_SRAM_UNCORR_ERR rw — Hard Slice 1 SRAM uncorrectable error interrupt test
  [4] ENC1_ASF_SRAM_CORR_ERR rw — Hard Slice 1 SRAM correctable error interrupt test
  [3] ENC0_SELF_CHK_ERR rw — Hard Slice 0 Encoder self-check uncorrectable error interrupt test
  [2] ENC0_OUT_CHK_ERR rw — Hard Slice 0 Encoder output checker uncorrectable error interrupt test
  [1] ENC0_ASF_SRAM_UNCORR_ERR rw — Hard Slice 0 SRAM uncorrectable error interrupt test
  [0] ENC0_ASF_SRAM_CORR_ERR rw — Hard Slice 0 SRAM correctable error interrupt test
0x30F20 EDP_CORE_ENC0_ASF_SRAM_CORR_P ro — Hard Slice 0 Status register for SRAM uncorrectable fault
  [25:24] ASF_SRAM_CORR_FAULT_INST — Last SRAM instance that generated fault.
  [23:0] ASF_SRAM_CORR_FAULT_ADDR — Last SRAM address that generated fault
0x30F24 EDP_CORE_ENC0_ASF_SRAM_UNCORR_P ro — Hard Slice 0 Status register for SRAM uncorrectable fault
  [25:24] ASF_SRAM_UNCORR_FAULT_INST — Last SRAM instance that generated fault.
  [23:0] ASF_SRAM_UNCORR_FAULT_ADDR — Last SRAM address that generated fault
0x30F28 EDP_CORE_ENC1_ASF_SRAM_CORR_P ro — Hard Slice 1 Status register for SRAM uncorrectable fault
  fields as EDP_CORE_ENC0_ASF_SRAM_CORR_P
0x30F2C EDP_CORE_ENC1_ASF_SRAM_UNCORR_P ro — Hard Slice 1 Status register for SRAM uncorrectable fault
  fields as EDP_CORE_ENC0_ASF_SRAM_UNCORR_P
0x30F30 EDP_CORE_ENC0_ASF_CSR_CHK_TEST_P — Hard Slice 0 Test for CSR protection expected CRC
  [15:0] ENC0_ASF_CSR_CHK_TEST rw — Each bit of the expected CRC can be corrupted separately [one bit at a time] using this register.
0x30F34 EDP_CORE_ENC1_ASF_CSR_CHK_TEST_P — Hard Slice 1 Test for CSR protection expected CRC
  [15:0] ENC1_ASF_CSR_CHK_TEST rw — Each bit of the expected CRC can be corrupted separately [one bit at a time] using this register.
0x30F38 EDP_CORE_ENC0_ASF_SELF_CHK_TEST_P — Hard Slice 0 Test for Self Check expected CRC
  [15:0] ENC0_ASF_SELF_CHK_TEST rw — Each bit of the expected CRC can be corrupted separately [one bit at a time] using this register.
0x30F3C EDP_CORE_ENC1_ASF_SELF_CHK_TEST_P — Hard Slice 1 Test for Self Check expected CRC
  [15:0] ENC1_ASF_SELF_CHK_TEST rw — Each bit of the expected CRC can be corrupted separately [one bit at a time] using this register.
0x30F40 EDP_CORE_ENC0_ASF_OUT_CHK_TEST_P — Hard Slice 0 Test for Output Checker. Each bit (one at a time) can used to corrupt various input/parameter values of the module.
  [8] END_FRAME_OUT_STUCK1_ERR rw, [7] END_LINE_OUT_STUCK1_ERR rw, [6] END_CHUNK_STUCK1_ERR rw, [5] VALID_OUT_STUCK1_ERR rw, [4] DATA_OUT_STUCK1_ERR rw, [3] VALID_STUCK0_ERR rw, [2] NVB_VALUE_ERR rw, [1] LINE_CNT_ERR rw, [0] BYTE_CNT_ERR rw
0x30F44 EDP_CORE_ENC1_ASF_OUT_CHK_TEST_P — Hard Slice 1 Test for Output Checker. Each bit (one at a time) can used to corrupt various input/parameter values of the module.
  fields as EDP_CORE_ENC0_ASF_OUT_CHK_TEST_P
